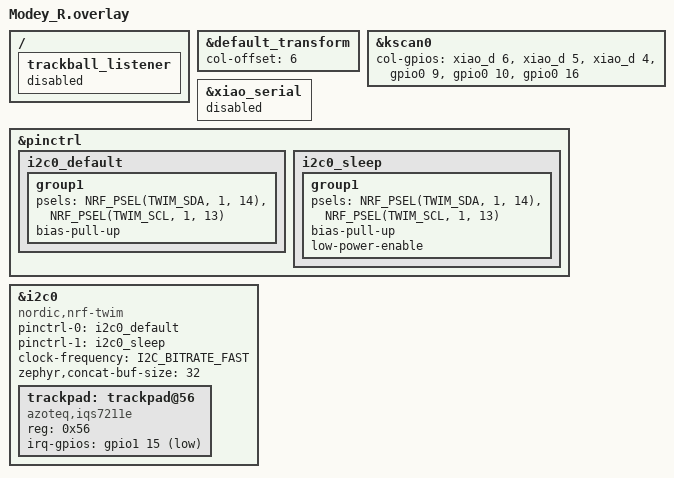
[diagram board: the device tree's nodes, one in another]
#include "Modey.dtsi"
#include <input/processors.dtsi>
#include <dt-bindings/zmk/input_transform.h>

&default_transform {
    col-offset = <6>;
};

&kscan0 {
        col-gpios =
        <&xiao_d 6 GPIO_ACTIVE_HIGH>,
        <&xiao_d 5 GPIO_ACTIVE_HIGH>,
        <&xiao_d 4 GPIO_ACTIVE_HIGH>,
        <&gpio0 9 GPIO_ACTIVE_HIGH>,
        <&gpio0 10 GPIO_ACTIVE_HIGH>,
        <&gpio0 16 GPIO_ACTIVE_HIGH>;
};

&xiao_serial {
        status = "disabled";
};

/ {
    trackball_listener {
       status = "disabled";
    };
};

&pinctrl {
    i2c0_default: i2c0_default {
        group1 {
            psels = <NRF_PSEL(TWIM_SDA, 1, 14)>,
                    <NRF_PSEL(TWIM_SCL, 1, 13)>;
            bias-pull-up;
        };
    };

    i2c0_sleep: i2c0_sleep {
        group1 {
            psels = <NRF_PSEL(TWIM_SDA, 1, 14)>,
                    <NRF_PSEL(TWIM_SCL, 1, 13)>;
            bias-pull-up;
            low-power-enable;
        };
    };
};

&i2c0 {
    status = "okay";
    compatible = "nordic,nrf-twim";
    pinctrl-0 = <&i2c0_default>;
    pinctrl-1 = <&i2c0_sleep>;
    pinctrl-names = "default", "sleep";
    clock-frequency = <I2C_BITRATE_FAST>;
    zephyr,concat-buf-size = <32>;

    trackpad: trackpad@56 {
        status = "okay";
        compatible = "azoteq,iqs7211e";
        reg = <0x56>;
        irq-gpios = <&gpio1 15 (GPIO_ACTIVE_LOW | GPIO_PULL_UP)>;
        // scroller-mode;
        // v-invert;
    };
};
